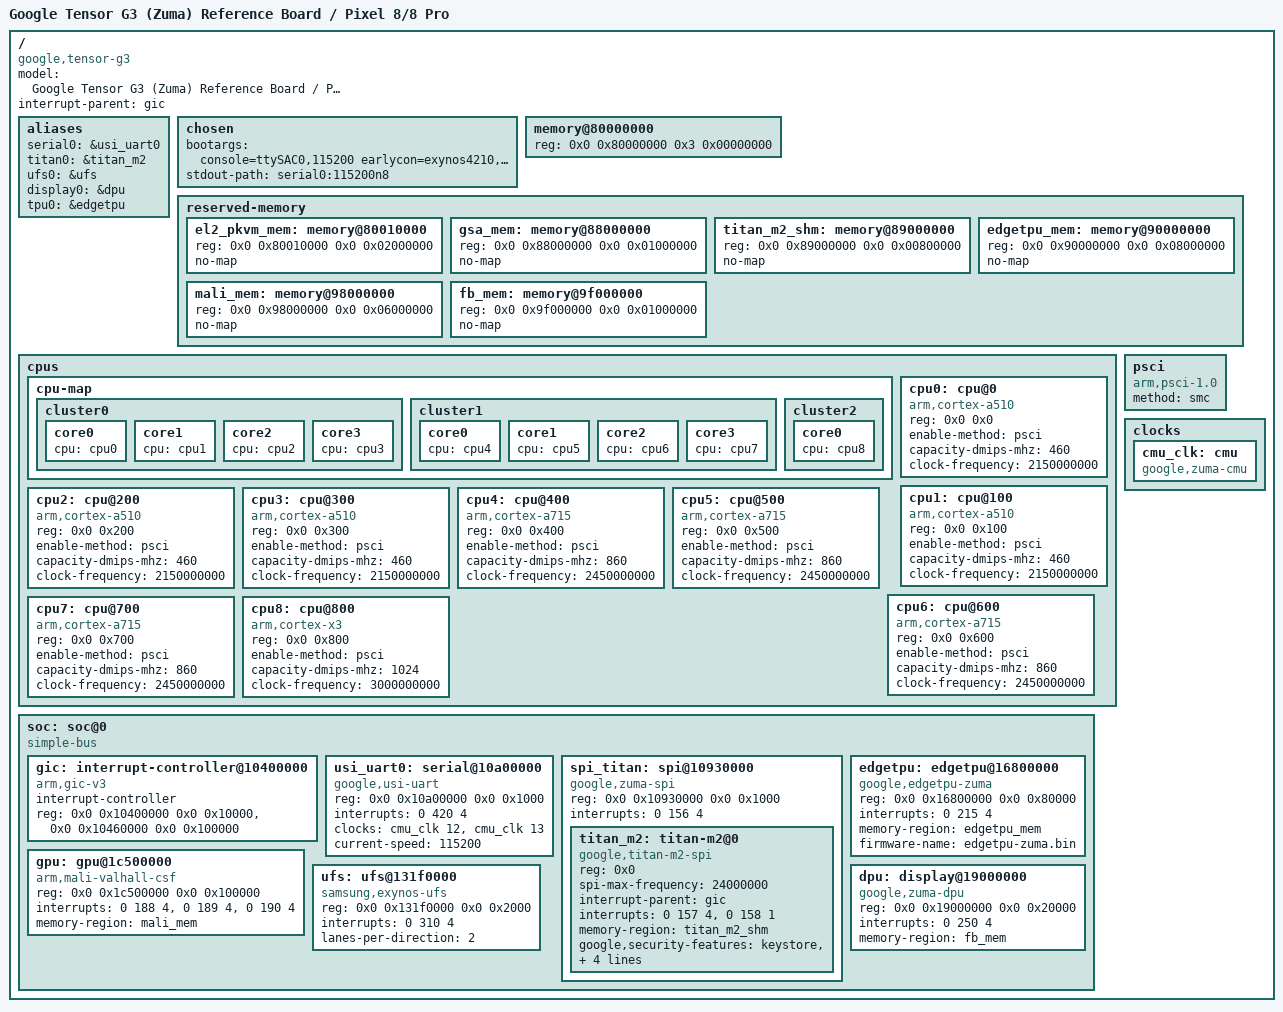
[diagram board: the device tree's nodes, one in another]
// PravahOS Device Tree Source for Google Tensor G3 / G4 (GS201 / Zuma / Zuma Pro)
// Target: Google Pixel 8 / 8 Pro / Pixel 9 Development Platform
/dts-v1/;

/memreserve/ 0x80000000 0x00010000;

/ {
	model = "Google Tensor G3 (Zuma) Reference Board / Pixel 8/8 Pro";
	compatible = "google,tensor-g3", "google,zuma-husky", "google,zuma-shiba", "google,zuma";
	#address-cells = <2>;
	#size-cells = <2>;
	interrupt-parent = <&gic>;

	aliases {
		serial0 = &usi_uart0;
		titan0 = &titan_m2;
		ufs0 = &ufs;
		display0 = &dpu;
		tpu0 = &edgetpu;
	};

	chosen {
		bootargs = "console=ttySAC0,115200 earlycon=exynos4210,0x10a00000 pravah.titan_m2=1 root=/dev/pravah_root init=/bin/init loglevel=7 pravah.platform=tensor-g3";
		stdout-path = "serial0:115200n8";
	};

	memory@80000000 {
		device_type = "memory";
		/* 12 GB / 16 GB LPDDR5X at base address 0x0000000080000000 */
		reg = <0x0 0x80000000 0x3 0x00000000>;
	};

	reserved-memory {
		#address-cells = <2>;
		#size-cells = <2>;
		ranges;

		el2_pkvm_mem: memory@80010000 {
			/* Protected KVM / TrustZone memory partition */
			reg = <0x0 0x80010000 0x0 0x02000000>;
			no-map;
		};

		gsa_mem: memory@88000000 {
			/* Google Security Architecture / Keymaster enclave buffer */
			reg = <0x0 0x88000000 0x0 0x01000000>;
			no-map;
		};

		titan_m2_shm: memory@89000000 {
			/* Titan M2 Hardware Security Enclave Shared Mailbox Buffer */
			reg = <0x0 0x89000000 0x0 0x00800000>;
			no-map;
		};

		edgetpu_mem: memory@90000000 {
			/* Google EdgeTPU tensor cache and model weight buffer */
			reg = <0x0 0x90000000 0x0 0x08000000>;
			no-map;
		};

		mali_mem: memory@98000000 {
			/* Mali-G715 Immortalis GPU carveout */
			reg = <0x0 0x98000000 0x0 0x06000000>;
			no-map;
		};

		fb_mem: memory@9f000000 {
			/* Framebuffer continuous display handoff */
			reg = <0x0 0x9f000000 0x0 0x01000000>;
			no-map;
		};
	};

	cpus {
		#address-cells = <2>;
		#size-cells = <0>;

		/* Tensor G3 9-core architecture: 1 Prime + 4 Mid + 4 Little */
		cpu-map {
			cluster0 {
				core0 {
					cpu = <&cpu0>;
				};
				core1 {
					cpu = <&cpu1>;
				};
				core2 {
					cpu = <&cpu2>;
				};
				core3 {
					cpu = <&cpu3>;
				};
			};

			cluster1 {
				core0 {
					cpu = <&cpu4>;
				};
				core1 {
					cpu = <&cpu5>;
				};
				core2 {
					cpu = <&cpu6>;
				};
				core3 {
					cpu = <&cpu7>;
				};
			};

			cluster2 {
				core0 {
					cpu = <&cpu8>;
				};
			};
		};

		/* 4x Cortex-A510 Little cores @ 2.15 GHz */
		cpu0: cpu@0 {
			device_type = "cpu";
			compatible = "arm,cortex-a510", "arm,armv9";
			reg = <0x0 0x0>;
			enable-method = "psci";
			capacity-dmips-mhz = <460>;
			clock-frequency = <2150000000>;
		};

		cpu1: cpu@100 {
			device_type = "cpu";
			compatible = "arm,cortex-a510", "arm,armv9";
			reg = <0x0 0x100>;
			enable-method = "psci";
			capacity-dmips-mhz = <460>;
			clock-frequency = <2150000000>;
		};

		cpu2: cpu@200 {
			device_type = "cpu";
			compatible = "arm,cortex-a510", "arm,armv9";
			reg = <0x0 0x200>;
			enable-method = "psci";
			capacity-dmips-mhz = <460>;
			clock-frequency = <2150000000>;
		};

		cpu3: cpu@300 {
			device_type = "cpu";
			compatible = "arm,cortex-a510", "arm,armv9";
			reg = <0x0 0x300>;
			enable-method = "psci";
			capacity-dmips-mhz = <460>;
			clock-frequency = <2150000000>;
		};

		/* 4x Cortex-A715 Mid cores @ 2.45 GHz */
		cpu4: cpu@400 {
			device_type = "cpu";
			compatible = "arm,cortex-a715", "arm,armv9";
			reg = <0x0 0x400>;
			enable-method = "psci";
			capacity-dmips-mhz = <860>;
			clock-frequency = <2450000000>;
		};

		cpu5: cpu@500 {
			device_type = "cpu";
			compatible = "arm,cortex-a715", "arm,armv9";
			reg = <0x0 0x500>;
			enable-method = "psci";
			capacity-dmips-mhz = <860>;
			clock-frequency = <2450000000>;
		};

		cpu6: cpu@600 {
			device_type = "cpu";
			compatible = "arm,cortex-a715", "arm,armv9";
			reg = <0x0 0x600>;
			enable-method = "psci";
			capacity-dmips-mhz = <860>;
			clock-frequency = <2450000000>;
		};

		cpu7: cpu@700 {
			device_type = "cpu";
			compatible = "arm,cortex-a715", "arm,armv9";
			reg = <0x0 0x700>;
			enable-method = "psci";
			capacity-dmips-mhz = <860>;
			clock-frequency = <2450000000>;
		};

		/* 1x Cortex-X3 Prime core @ 3.00 GHz */
		cpu8: cpu@800 {
			device_type = "cpu";
			compatible = "arm,cortex-x3", "arm,armv9";
			reg = <0x0 0x800>;
			enable-method = "psci";
			capacity-dmips-mhz = <1024>;
			clock-frequency = <3000000000>;
		};
	};

	psci {
		compatible = "arm,psci-1.0", "arm,psci-0.2";
		method = "smc";
	};

	clocks {
		cmu_clk: cmu {
			compatible = "google,zuma-cmu";
			#clock-cells = <1>;
			#reset-cells = <1>;
		};
	};

	soc: soc@0 {
		compatible = "simple-bus";
		#address-cells = <2>;
		#size-cells = <2>;
		ranges;

		/* ARM Generic Interrupt Controller v3 */
		gic: interrupt-controller@10400000 {
			compatible = "arm,gic-v3";
			#interrupt-cells = <3>;
			interrupt-controller;
			reg = <0x0 0x10400000 0x0 0x10000>,
			      <0x0 0x10460000 0x0 0x100000>;
		};

		/* Exynos USI UART Serial Console */
		usi_uart0: serial@10a00000 {
			compatible = "google,usi-uart", "samsung,exynos-uart";
			reg = <0x0 0x10a00000 0x0 0x1000>;
			interrupts = <0 420 4>;
			clock-names = "uart", "clk_uart_baud0";
			clocks = <&cmu_clk 12>, <&cmu_clk 13>;
			current-speed = <115200>;
			status = "okay";
		};

		/* Titan M2 Hardware Security Enclave (Discrete Security Chip SPI Bus) */
		spi_titan: spi@10930000 {
			compatible = "google,zuma-spi";
			reg = <0x0 0x10930000 0x0 0x1000>;
			interrupts = <0 156 4>;
			#address-cells = <1>;
			#size-cells = <0>;
			status = "okay";

			titan_m2: titan-m2@0 {
				compatible = "google,titan-m2-spi", "google,titan-m2";
				reg = <0x0>;
				spi-max-frequency = <24000000>;
				interrupt-parent = <&gic>;
				interrupts = <0 157 4>, <0 158 1>;
				interrupt-names = "irq_resp", "irq_tamper";
				memory-region = <&titan_m2_shm>;
				google,security-features = "keystore", "attestation", "hash-ledger", "tamper-resist", "anti-rollback";
				google,slot-count = <16>;
				google,tamper-protection-flags = <0x7f>;
				status = "okay";
			};
		};

		/* Google EdgeTPU Accelerator */
		edgetpu: edgetpu@16800000 {
			compatible = "google,edgetpu-zuma", "google,edgetpu";
			reg = <0x0 0x16800000 0x0 0x80000>;
			interrupts = <0 215 4>;
			memory-region = <&edgetpu_mem>;
			firmware-name = "edgetpu-zuma.bin";
			status = "okay";
		};

		/* ARM Mali-G715 Immortalis GPU */
		gpu: gpu@1c500000 {
			compatible = "arm,mali-valhall-csf", "arm,mali-g715";
			reg = <0x0 0x1c500000 0x0 0x100000>;
			interrupts = <0 188 4>, <0 189 4>, <0 190 4>;
			interrupt-names = "job", "mmu", "gpu";
			memory-region = <&mali_mem>;
			status = "okay";
		};

		/* Exynos / Tensor UFS Controller */
		ufs: ufs@131f0000 {
			compatible = "samsung,exynos-ufs", "jedec,ufs-2.0";
			reg = <0x0 0x131f0000 0x0 0x2000>;
			interrupts = <0 310 4>;
			lanes-per-direction = <2>;
			status = "okay";
		};

		/* Display Processor Unit (DPU) */
		dpu: display@19000000 {
			compatible = "google,zuma-dpu";
			reg = <0x0 0x19000000 0x0 0x20000>;
			interrupts = <0 250 4>;
			memory-region = <&fb_mem>;
			status = "okay";
		};
	};
};
